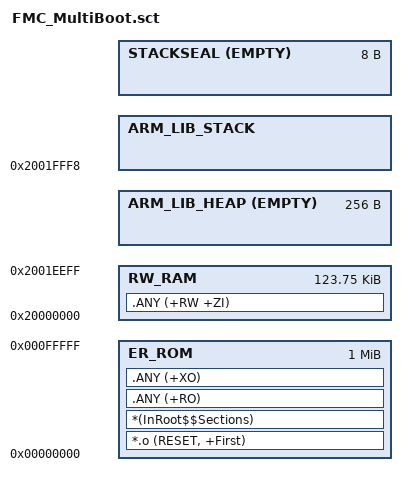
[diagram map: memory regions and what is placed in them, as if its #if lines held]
#! armclang -E --target=arm-arm-none-eabi -mcpu=cortex-m4 -xc
; command above MUST be in first line (no comment above!)

;Note: Add '-mcmse' to first line if your software model is "Secure Mode".
;      #! armclang -E --target=arm-arm-none-eabi -mcpu=<CPU> -xc -mcmse

#ifndef FLASH_BASE
    #define FLASH_BASE      0x00000000
#endif

#ifndef FLASH_SIZE
    #define FLASH_SIZE      0x00100000
#endif

#ifndef SRAM_SIZE
    #define SRAM_SIZE       0x00020000
#endif

#ifndef STACK_SIZE
    #define STACK_SIZE      0x00001000
#endif

#ifndef HEAP_SIZE
    #define HEAP_SIZE       0x00000100
#endif

/* ----------------------------------------------------------------------------
  Flash Base Address and Size Configuration
 *----------------------------------------------------------------------------*/
#define __FLASH_BASE        FLASH_BASE
#define __FLASH_SIZE        FLASH_SIZE

/* ----------------------------------------------------------------------------
  SRAM Base Address and Size Configuration
 *----------------------------------------------------------------------------*/
#define __SRAM_BASE         0x20000000
#define __SRAM_SIZE         SRAM_SIZE

/* ----------------------------------------------------------------------------
  Stack / Heap Size Configuration
 *----------------------------------------------------------------------------*/
#define __STACK_SIZE        STACK_SIZE
#define __HEAP_SIZE         HEAP_SIZE

/* ----------------------------------------------------------------------------
  Stack seal size definition
 *----------------------------------------------------------------------------*/
#if defined (__ARM_FEATURE_CMSE) && (__ARM_FEATURE_CMSE == 3U)
#define __STACKSEAL_SIZE   ( 8 )
#else
#define __STACKSEAL_SIZE   ( 0 )
#endif

/*----------------------------------------------------------------------------
  User Stack & Heap boundary definition
 *----------------------------------------------------------------------------*/
#define __STACK_TOP    (__SRAM_BASE + __SRAM_SIZE - __STACKSEAL_SIZE)      /* starts at end of RAM - 8 byte stack seal */
#define __HEAP_BASE    (AlignExpr(+0, 8))                                  /* starts after RW_RAM section, 8 byte aligned */

/*----------------------------------------------------------------------------
  Region base & size definition
 *----------------------------------------------------------------------------*/
#define __RO_BASE          ( __FLASH_BASE )
#define __RO_SIZE          ( __FLASH_SIZE )

#define __RW_BASE          ( __SRAM_BASE )
#define __RW_SIZE          ( __SRAM_SIZE - __STACK_SIZE - __HEAP_SIZE )

/*----------------------------------------------------------------------------
  Scatter Region definition
 *----------------------------------------------------------------------------*/
LR_ROM __RO_BASE __RO_SIZE  {                         ; load region size_region
    ER_ROM __RO_BASE __RO_SIZE  {                     ; load address = execution address
        *.o (RESET, +First)
        *(InRoot$$Sections)
        .ANY (+RO)
        .ANY (+XO)
    }

    RW_RAM __RW_BASE __RW_SIZE  {                     ; RW data
        .ANY (+RW +ZI)
    }

#if __HEAP_SIZE > 0
    ARM_LIB_HEAP  __HEAP_BASE EMPTY  __HEAP_SIZE  {   ; Reserve empty region for heap
    }
#endif

    ARM_LIB_STACK __STACK_TOP EMPTY - __STACK_SIZE {  ; Reserve empty region for stack
    }
    
#if defined (__ARM_FEATURE_CMSE) && (__ARM_FEATURE_CMSE == 3U)
    STACKSEAL +0 EMPTY __STACKSEAL_SIZE {             ; Reserve empty region for stack seal immediately after stack
    }
#endif
}
